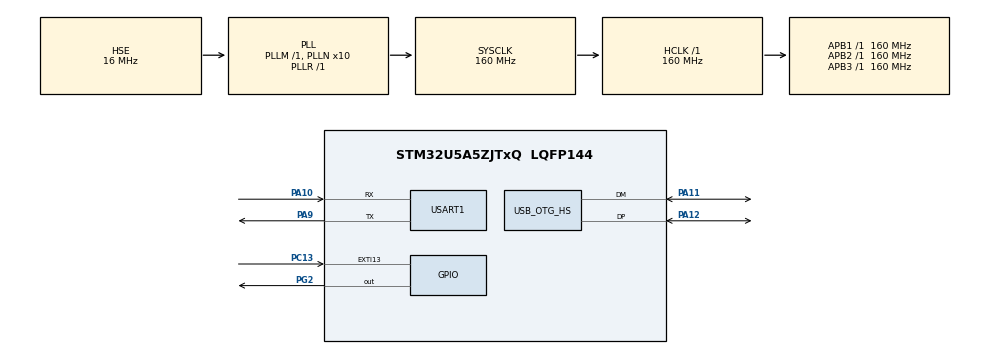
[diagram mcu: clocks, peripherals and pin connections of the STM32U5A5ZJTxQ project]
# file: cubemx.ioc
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CORTEX_M33_NS.userName=CORTEX_M33
GPDMA1.CIRCULARMODE_GPDMACH0=ENABLE
GPDMA1.DESTINC_GPDMACH0=DMA_DINC_INCREMENTED
GPDMA1.IPHANDLE_GPDMACH0-SIMPLEREQUEST_GPDMACH0=__NULL
GPDMA1.PRIORITY_LL_GPDMACH13=DMA_LOW_PRIORITY_HIGH_WEIGHT
GPDMA1.REQUEST_GPDMACH0=GPDMA1_REQUEST_USART1_RX
Mcu.Family=STM32U5
Mcu.Name=STM32U5A5ZJTxQ
Mcu.Package=LQFP144
NVIC.EXTI13_IRQn=true\:6\:0\:true\:false\:true\:true\:true\:true
NVIC.GPDMA1_Channel0_IRQn=true\:0\:0\:false\:false\:true\:false\:true\:true
NVIC.GPDMA1_Channel13_IRQn=true\:0\:0\:false\:false\:true\:true\:true\:true
NVIC.OTG_HS_IRQn=true\:6\:0\:true\:false\:true\:true\:true\:true
NVIC.PriorityGroup=NVIC_PRIORITYGROUP_4
PA10.GPIO_Speed=GPIO_SPEED_FREQ_HIGH
PA10.Mode=Asynchronous
PA10.Signal=USART1_RX
PA11.Mode=Internal_Phy_Device
PA11.Signal=USB_OTG_HS_DM
PA12.Mode=Internal_Phy_Device
PA12.Signal=USB_OTG_HS_DP
PA13\ (JTMS/SWDIO).Mode=Serial_Wire
PA13\ (JTMS/SWDIO).Signal=DEBUG_JTMS-SWDIO
PA14\ (JTCK/SWCLK).Mode=Serial_Wire
PA14\ (JTCK/SWCLK).Signal=DEBUG_JTCK-SWCLK
PA9.GPIO_Speed=GPIO_SPEED_FREQ_HIGH
PA9.Mode=Asynchronous
PA9.Signal=USART1_TX
PC13.Signal=GPXTI13
PC14-OSC32_IN\ (PC14).Mode=LSE-External-Oscillator
PC14-OSC32_IN\ (PC14).Signal=RCC_OSC32_IN
PC15-OSC32_OUT\ (PC15).Mode=LSE-External-Oscillator
PC15-OSC32_OUT\ (PC15).Signal=RCC_OSC32_OUT
PG2.Signal=GPIO_Output
PH0-OSC_IN\ (PH0).Mode=HSE-External-Oscillator
PH0-OSC_IN\ (PH0).Signal=RCC_OSC_IN
PH1-OSC_OUT\ (PH1).Mode=HSE-External-Oscillator
PH1-OSC_OUT\ (PH1).Signal=RCC_OSC_OUT
ProjectManager.HeapSize=0x200
ProjectManager.StackSize=0x400
ProjectManager.TargetToolchain=STM32CubeIDE
RCC.ADCFreq_Value=16000000
RCC.AHBFreq_Value=160000000
RCC.APB1Freq_Value=160000000
RCC.APB1TimFreq_Value=160000000
RCC.APB2Freq_Value=160000000
RCC.APB2TimFreq_Value=160000000
RCC.APB3Freq_Value=160000000
RCC.CortexFreq_Value=160000000
RCC.EPOD_VALUE=16000000
RCC.HCLKFreq_Value=160000000
RCC.HSE_VALUE=16000000
RCC.HSI48_VALUE=48000000
RCC.HSI_VALUE=16000000
RCC.LSIDIV_VALUE=32000
RCC.LockedElements=PLLFRACN
RCC.MSI_VALUE=4000000
RCC.PLL1R=1
RCC.PLLFRACN=0
RCC.PLLN=10
RCC.PLLSourceVirtual=RCC_PLLSOURCE_HSE
RCC.SYSCLKFreq_VALUE=160000000
RCC.SYSCLKSource=RCC_SYSCLKSOURCE_PLLCLK
RCC.USBPHYCLockSelection=RCC_USBPHYCLKSOURCE_HSE
RCC.VCOOutputFreq_Value=160000000
TIM17.AutoReloadPreload=TIM_AUTORELOAD_PRELOAD_ENABLE
TIM17.PeriodNoDither=99
TIM17.Prescaler=19
TIM2.Prescaler=159
USART1.VirtualMode-Asynchronous=VM_ASYNC
USB_OTG_HS.DeviceSpeed=PCD_SPEED_HIGH
USB_OTG_HS.VirtualMode=Device_HS
USB_OTG_HS.dma_enable=DISABLE
VP_GPDMA1_VS_GPDMACH0.Mode=SIMPLEREQUEST_GPDMACH0
VP_GPDMA1_VS_GPDMACH13.Mode=LINKEDLIST_GPDMACH13
VP_ICACHE_VS_ICACHE.Mode=DefaultMode
VP_LPBAMQUEUE_VS_QUEUE.Mode=QUEUEMODE
VP_LPBAM_VS_SIG1.Mode=SmartRun
VP_LPBAM_VS_SIG4.Mode=LPDMA1
VP_MEMORYMAP_VS_MEMORYMAP.Mode=CurAppReg
VP_PWR_VS_SECSignals.Mode=Security/Privilege
VP_RTC_VS_RTC_Activate.Mode=RTC_Enabled
VP_RTC_VS_RTC_Calendar.Mode=RTC_Calendar
VP_TIM17_VS_ClockSourceINT.Mode=Enable_Timer
VP_TIM2_VS_ClockSourceINT.Mode=Internal
board=custom

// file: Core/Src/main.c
/* USER CODE BEGIN Header */
/**
  ******************************************************************************
  * @file           : main.c
  * @brief          : Main program body
  ******************************************************************************
  * @attention
  *
  * Copyright (c) 2025 STMicroelectronics.
  * All rights reserved.
  *
  * This software is licensed under terms that can be found in the LICENSE file
  * in the root directory of this software component.
  * If no LICENSE file comes with this software, it is provided AS-IS.
  *
  ******************************************************************************
  */
/* USER CODE END Header */
#include "main.h"

DMA_HandleTypeDef handle_GPDMA1_Channel13;

RTC_HandleTypeDef hrtc;

TIM_HandleTypeDef htim2;
TIM_HandleTypeDef htim17;

UART_HandleTypeDef huart1;
DMA_NodeTypeDef Node_GPDMA1_Channel0;
DMA_QListTypeDef List_GPDMA1_Channel0;
DMA_HandleTypeDef handle_GPDMA1_Channel0;

PCD_HandleTypeDef hpcd_USB_OTG_HS;

void SystemClock_Config(void);
static void MX_GPIO_Init(void);
static void MX_GPDMA1_Init(void);
static void MX_USB_OTG_HS_PCD_Init(void);
static void MX_RTC_Init(void);
static void MX_ICACHE_Init(void);
static void MX_USART1_UART_Init(void);
static void MX_TIM2_Init(void);
static void MX_TIM17_Init(void);

int main(void)
{

  /* MCU Configuration--------------------------------------------------------*/

  /* Reset of all peripherals, Initializes the Flash interface and the Systick. */
  HAL_Init();

  /* Configure the system clock */
  SystemClock_Config();

  /* Initialize all configured peripherals */
  MX_GPIO_Init();
  MX_GPDMA1_Init();
  MX_USB_OTG_HS_PCD_Init();
  MX_RTC_Init();
  MX_ICACHE_Init();
  MX_USART1_UART_Init();
  MX_TIM2_Init();
  MX_TIM17_Init();
  /* USER CODE BEGIN 2 */

  char message[] = "Hello World...\r\n";
  /* USER CODE END 2 */

  /* Infinite loop */
  while (1)
  {
	  HAL_UART_Transmit(&huart1, (uint8_t*)message, strlen(message), 0);
  }
}

void SystemClock_Config(void)
{
  RCC_OscInitTypeDef RCC_OscInitStruct = {0};
  RCC_ClkInitTypeDef RCC_ClkInitStruct = {0};

  /** Configure the main internal regulator output voltage
  */
  if (HAL_PWREx_ControlVoltageScaling(PWR_REGULATOR_VOLTAGE_SCALE1) != HAL_OK)
  {
    Error_Handler();
  }

  /** Initializes the CPU, AHB and APB buses clocks
  */
  RCC_OscInitStruct.OscillatorType = RCC_OSCILLATORTYPE_LSI|RCC_OSCILLATORTYPE_HSE;
  RCC_OscInitStruct.HSEState = RCC_HSE_ON;
  RCC_OscInitStruct.LSIState = RCC_LSI_ON;
  RCC_OscInitStruct.LSIDiv = RCC_LSI_DIV1;
  RCC_OscInitStruct.PLL.PLLState = RCC_PLL_ON;
  RCC_OscInitStruct.PLL.PLLSource = RCC_PLLSOURCE_HSE;
  RCC_OscInitStruct.PLL.PLLMBOOST = RCC_PLLMBOOST_DIV1;
  RCC_OscInitStruct.PLL.PLLM = 1;
  RCC_OscInitStruct.PLL.PLLN = 10;
  RCC_OscInitStruct.PLL.PLLP = 2;
  RCC_OscInitStruct.PLL.PLLQ = 2;
  RCC_OscInitStruct.PLL.PLLR = 1;
  RCC_OscInitStruct.PLL.PLLRGE = RCC_PLLVCIRANGE_1;
  RCC_OscInitStruct.PLL.PLLFRACN = 0;
  if (HAL_RCC_OscConfig(&RCC_OscInitStruct) != HAL_OK)
  {
    Error_Handler();
  }

  /** Initializes the CPU, AHB and APB buses clocks
  */
  RCC_ClkInitStruct.ClockType = RCC_CLOCKTYPE_HCLK|RCC_CLOCKTYPE_SYSCLK
                              |RCC_CLOCKTYPE_PCLK1|RCC_CLOCKTYPE_PCLK2
                              |RCC_CLOCKTYPE_PCLK3;
  RCC_ClkInitStruct.SYSCLKSource = RCC_SYSCLKSOURCE_PLLCLK;
  RCC_ClkInitStruct.AHBCLKDivider = RCC_SYSCLK_DIV1;
  RCC_ClkInitStruct.APB1CLKDivider = RCC_HCLK_DIV1;
  RCC_ClkInitStruct.APB2CLKDivider = RCC_HCLK_DIV1;
  RCC_ClkInitStruct.APB3CLKDivider = RCC_HCLK_DIV1;

  if (HAL_RCC_ClockConfig(&RCC_ClkInitStruct, FLASH_LATENCY_4) != HAL_OK)
  {
    Error_Handler();
  }
}

static void MX_GPDMA1_Init(void)
{

  /* Peripheral clock enable */
  __HAL_RCC_GPDMA1_CLK_ENABLE();

  /* GPDMA1 interrupt Init */
    HAL_NVIC_SetPriority(GPDMA1_Channel0_IRQn, 0, 0);
    HAL_NVIC_EnableIRQ(GPDMA1_Channel0_IRQn);
    HAL_NVIC_SetPriority(GPDMA1_Channel13_IRQn, 0, 0);
    HAL_NVIC_EnableIRQ(GPDMA1_Channel13_IRQn);

  handle_GPDMA1_Channel13.Instance = GPDMA1_Channel13;
  handle_GPDMA1_Channel13.InitLinkedList.Priority = DMA_LOW_PRIORITY_HIGH_WEIGHT;
  handle_GPDMA1_Channel13.InitLinkedList.LinkStepMode = DMA_LSM_FULL_EXECUTION;
  handle_GPDMA1_Channel13.InitLinkedList.LinkAllocatedPort = DMA_LINK_ALLOCATED_PORT0;
  handle_GPDMA1_Channel13.InitLinkedList.TransferEventMode = DMA_TCEM_LAST_LL_ITEM_TRANSFER;
  handle_GPDMA1_Channel13.InitLinkedList.LinkedListMode = DMA_LINKEDLIST_NORMAL;
  if (HAL_DMAEx_List_Init(&handle_GPDMA1_Channel13) != HAL_OK)
  {
    Error_Handler();
  }
  if (HAL_DMA_ConfigChannelAttributes(&handle_GPDMA1_Channel13, DMA_CHANNEL_NPRIV) != HAL_OK)
  {
    Error_Handler();
  }

}

static void MX_ICACHE_Init(void)
{

  /** Enable instruction cache (default 2-ways set associative cache)
  */
  if (HAL_ICACHE_Enable() != HAL_OK)
  {
    Error_Handler();
  }

}

static void MX_RTC_Init(void)
{

  RTC_PrivilegeStateTypeDef privilegeState = {0};
  RTC_TimeTypeDef sTime = {0};
  RTC_DateTypeDef sDate = {0};

  /** Initialize RTC Only
  */
  hrtc.Instance = RTC;
  hrtc.Init.HourFormat = RTC_HOURFORMAT_24;
  hrtc.Init.AsynchPrediv = 127;
  hrtc.Init.SynchPrediv = 255;
  hrtc.Init.OutPut = RTC_OUTPUT_DISABLE;
  hrtc.Init.OutPutRemap = RTC_OUTPUT_REMAP_NONE;
  hrtc.Init.OutPutPolarity = RTC_OUTPUT_POLARITY_HIGH;
  hrtc.Init.OutPutType = RTC_OUTPUT_TYPE_OPENDRAIN;
  hrtc.Init.OutPutPullUp = RTC_OUTPUT_PULLUP_NONE;
  hrtc.Init.BinMode = RTC_BINARY_NONE;
  if (HAL_RTC_Init(&hrtc) != HAL_OK)
  {
    Error_Handler();
  }
  privilegeState.rtcPrivilegeFull = RTC_PRIVILEGE_FULL_NO;
  privilegeState.backupRegisterPrivZone = RTC_PRIVILEGE_BKUP_ZONE_NONE;
  privilegeState.backupRegisterStartZone2 = RTC_BKP_DR0;
  privilegeState.backupRegisterStartZone3 = RTC_BKP_DR0;
  if (HAL_RTCEx_PrivilegeModeSet(&hrtc, &privilegeState) != HAL_OK)
  {
    Error_Handler();
  }

  /** Initialize RTC and set the Time and Date
  */
  sTime.Hours = 0x0;
  sTime.Minutes = 0x0;
  sTime.Seconds = 0x0;
  sTime.DayLightSaving = RTC_DAYLIGHTSAVING_NONE;
  sTime.StoreOperation = RTC_STOREOPERATION_RESET;
  if (HAL_RTC_SetTime(&hrtc, &sTime, RTC_FORMAT_BCD) != HAL_OK)
  {
    Error_Handler();
  }
  sDate.WeekDay = RTC_WEEKDAY_MONDAY;
  sDate.Month = RTC_MONTH_JANUARY;
  sDate.Date = 0x1;
  sDate.Year = 0x0;

  if (HAL_RTC_SetDate(&hrtc, &sDate, RTC_FORMAT_BCD) != HAL_OK)
  {
    Error_Handler();
  }

}

static void MX_TIM2_Init(void)
{

  TIM_ClockConfigTypeDef sClockSourceConfig = {0};
  TIM_MasterConfigTypeDef sMasterConfig = {0};

  htim2.Instance = TIM2;
  htim2.Init.Prescaler = 159;
  htim2.Init.CounterMode = TIM_COUNTERMODE_UP;
  htim2.Init.Period = 4294967295;
  htim2.Init.ClockDivision = TIM_CLOCKDIVISION_DIV1;
  htim2.Init.AutoReloadPreload = TIM_AUTORELOAD_PRELOAD_DISABLE;
  if (HAL_TIM_Base_Init(&htim2) != HAL_OK)
  {
    Error_Handler();
  }
  sClockSourceConfig.ClockSource = TIM_CLOCKSOURCE_INTERNAL;
  if (HAL_TIM_ConfigClockSource(&htim2, &sClockSourceConfig) != HAL_OK)
  {
    Error_Handler();
  }
  sMasterConfig.MasterOutputTrigger = TIM_TRGO_RESET;
  sMasterConfig.MasterSlaveMode = TIM_MASTERSLAVEMODE_DISABLE;
  if (HAL_TIMEx_MasterConfigSynchronization(&htim2, &sMasterConfig) != HAL_OK)
  {
    Error_Handler();
  }

}

static void MX_TIM17_Init(void)
{

  htim17.Instance = TIM17;
  htim17.Init.Prescaler = 19;
  htim17.Init.CounterMode = TIM_COUNTERMODE_UP;
  htim17.Init.Period = 99;
  htim17.Init.ClockDivision = TIM_CLOCKDIVISION_DIV1;
  htim17.Init.RepetitionCounter = 0;
  htim17.Init.AutoReloadPreload = TIM_AUTORELOAD_PRELOAD_ENABLE;
  if (HAL_TIM_Base_Init(&htim17) != HAL_OK)
  {
    Error_Handler();
  }

}

static void MX_USART1_UART_Init(void)
{

  huart1.Instance = USART1;
  huart1.Init.BaudRate = 115200;
  huart1.Init.WordLength = UART_WORDLENGTH_8B;
  huart1.Init.StopBits = UART_STOPBITS_1;
  huart1.Init.Parity = UART_PARITY_NONE;
  huart1.Init.Mode = UART_MODE_TX_RX;
  huart1.Init.HwFlowCtl = UART_HWCONTROL_NONE;
  huart1.Init.OverSampling = UART_OVERSAMPLING_16;
  huart1.Init.OneBitSampling = UART_ONE_BIT_SAMPLE_DISABLE;
  huart1.Init.ClockPrescaler = UART_PRESCALER_DIV1;
  huart1.AdvancedInit.AdvFeatureInit = UART_ADVFEATURE_NO_INIT;
  if (HAL_UART_Init(&huart1) != HAL_OK)
  {
    Error_Handler();
  }
  if (HAL_UARTEx_SetTxFifoThreshold(&huart1, UART_TXFIFO_THRESHOLD_1_8) != HAL_OK)
  {
    Error_Handler();
  }
  if (HAL_UARTEx_SetRxFifoThreshold(&huart1, UART_RXFIFO_THRESHOLD_1_8) != HAL_OK)
  {
    Error_Handler();
  }
  if (HAL_UARTEx_DisableFifoMode(&huart1) != HAL_OK)
  {
    Error_Handler();
  }

}

static void MX_USB_OTG_HS_PCD_Init(void)
{

  hpcd_USB_OTG_HS.Instance = USB_OTG_HS;
  hpcd_USB_OTG_HS.Init.dev_endpoints = 9;
  hpcd_USB_OTG_HS.Init.speed = PCD_SPEED_HIGH;
  hpcd_USB_OTG_HS.Init.phy_itface = USB_OTG_HS_EMBEDDED_PHY;
  hpcd_USB_OTG_HS.Init.Sof_enable = DISABLE;
  hpcd_USB_OTG_HS.Init.low_power_enable = DISABLE;
  hpcd_USB_OTG_HS.Init.lpm_enable = DISABLE;
  hpcd_USB_OTG_HS.Init.use_dedicated_ep1 = DISABLE;
  hpcd_USB_OTG_HS.Init.vbus_sensing_enable = DISABLE;
  hpcd_USB_OTG_HS.Init.dma_enable = DISABLE;
  if (HAL_PCD_Init(&hpcd_USB_OTG_HS) != HAL_OK)
  {
    Error_Handler();
  }

}

static void MX_GPIO_Init(void)
{
  GPIO_InitTypeDef GPIO_InitStruct = {0};

  /* GPIO Ports Clock Enable */
  __HAL_RCC_GPIOC_CLK_ENABLE();
  __HAL_RCC_GPIOH_CLK_ENABLE();
  __HAL_RCC_GPIOG_CLK_ENABLE();
  __HAL_RCC_GPIOA_CLK_ENABLE();

  /*Configure GPIO pin Output Level */
  HAL_GPIO_WritePin(GPIOG, GPIO_PIN_2, GPIO_PIN_RESET);

  /*Configure GPIO pin : PC13 */
  GPIO_InitStruct.Pin = GPIO_PIN_13;
  GPIO_InitStruct.Mode = GPIO_MODE_IT_RISING;
  GPIO_InitStruct.Pull = GPIO_NOPULL;
  HAL_GPIO_Init(GPIOC, &GPIO_InitStruct);

  /*Configure GPIO pin : PG2 */
  GPIO_InitStruct.Pin = GPIO_PIN_2;
  GPIO_InitStruct.Mode = GPIO_MODE_OUTPUT_PP;
  GPIO_InitStruct.Pull = GPIO_NOPULL;
  GPIO_InitStruct.Speed = GPIO_SPEED_FREQ_LOW;
  HAL_GPIO_Init(GPIOG, &GPIO_InitStruct);

  /* EXTI interrupt init*/
  HAL_NVIC_SetPriority(EXTI13_IRQn, 6, 0);
  HAL_NVIC_EnableIRQ(EXTI13_IRQn);

}

void Error_Handler(void)
{
  __disable_irq();
  while (1)
  {
  }
}
